# R7FA6T2BD register map
Vendor: Renesas Electronics Corporation; Series: RA6; File version: 1.40.00
CPU: CM33 r0p4, little endian, MPU, FPU, VTOR, 4 interrupt priority bits, 96 interrupts
Registers are 32-bit, read-write, reset 0x0 unless marked. A register's access mark holds for its fields unless they carry their own. Offsets are from the block's base; [hi:lo] are bit positions; {n}, {i} and the like mark numbered series; 'fields as' and 'values as' point back to an identical list.

## MSTP — Module Stop Control
Base 0x40084000
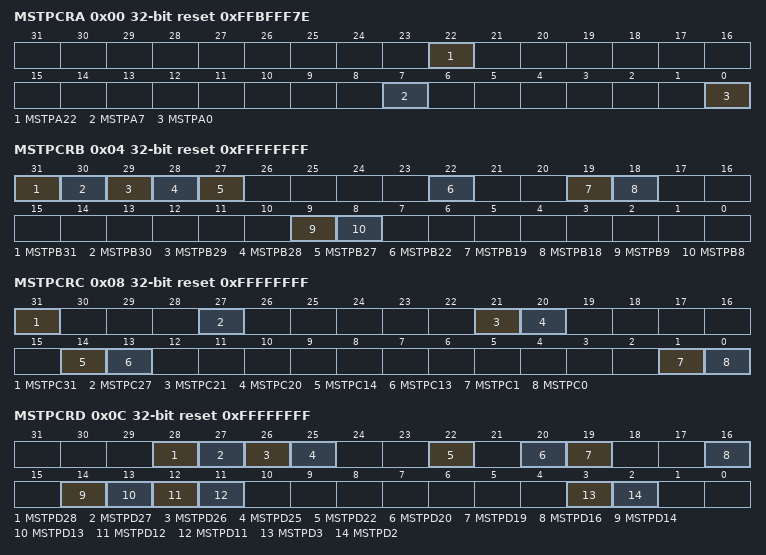
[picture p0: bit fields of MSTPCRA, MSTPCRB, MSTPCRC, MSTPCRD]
0x00 MSTPCRA reset 0xFFBFFF7E — Module Stop Control Register A
  [22] MSTPA22 — DMA Controller/Data Transfer Controller Module Stop
  [7] MSTPA7 — Standby SRAM Module Stop
  [0] MSTPA0 — SRAM0 Module Stop
0x04 MSTPCRB reset 0xFFFFFFFF — Module Stop Control Register B
  [31] MSTPB31 — Serial Communication Interface 0 Module Stop
  [30] MSTPB30 — Serial Communication Interface 1 Module Stop
  [29] MSTPB29 — Serial Communication Interface 2 Module Stop
  [28] MSTPB28 — Serial Communication Interface 3 Module Stop
  [27] MSTPB27 — Serial Communication Interface 4 Module Stop
  [22] MSTPB22 — Serial Communication Interface 9 Module Stop
  [19] MSTPB19 — Serial Peripheral Interface 0 Module Stop
  [18] MSTPB18 — Serial Peripheral Interface 1 Module Stop
  [9] MSTPB9 — I2C Bus Interface 0 Module Stop
  [8] MSTPB8 — I2C Bus Interface 1 Module Stop
0x08 MSTPCRC reset 0xFFFFFFFF — Module Stop Control Register C
  [31] MSTPC31 — Secure Cryptographic Engine Module Stop
  [27] MSTPC27 — CANFD Module Stop
  [21] MSTPC21 — IIR Filter Accelerator Module Stop
  [20] MSTPC20 — Trigonometric Function Unit Module Stop
  [14] MSTPC14 — Event Link Controller Module Stop
  [13] MSTPC13 — Data Operation Circuit Module Stop
  [1] MSTPC1 — Cyclic Redundancy Check Module Stop
  [0] MSTPC0 — Clock Frequency Accuracy Measurement Circuit Module Stop
0x0C MSTPCRD reset 0xFFFFFFFF — Module Stop Control Register D
  [28] MSTPD28 — High,Speed Analog Comparator 0 Module Stop
  [27] MSTPD27 — High,Speed Analog Comparator 1 Module Stop
  [26] MSTPD26 — High,Speed Analog Comparator 2 Module Stop
  [25] MSTPD25 — High,Speed Analog Comparator 3 Module Stop
  [22] MSTPD22 — Temperature Sensor Module Stop
  [20] MSTPD20 — 12-bit D/A Converter 0 Module Stop
  [19] MSTPD19 — 12-bit D/A Converter 1 Module Stop
  [16] MSTPD16 — A/D Converter Module Stop
  [14] MSTPD14 — Port Output Enable for GPT Group A Module Stop
  [13] MSTPD13 — Port Output Enable for GPT Group B Module Stop
  [12] MSTPD12 — Port Output Enable for GPT Group C Module Stop
  [11] MSTPD11 — Port Output Enable for GPT Group D Module Stop
  [3] MSTPD3 — Low Power Asynchronous General Purpose Timer 0 Module Stop
  [2] MSTPD2 — Low Power Asynchronous General Purpose Timer 1 Module Stop
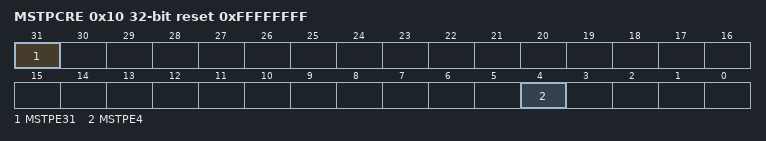
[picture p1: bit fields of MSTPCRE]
0x10 MSTPCRE reset 0xFFFFFFFF — Module Stop Control Register E
  [31] MSTPE31 — General PWM Timer and PWM Delay Generation Circuit Module Stop
  [4] MSTPE4 — Key Interrupt Function Module Stop

## KINT — Key Interrupt Function
Base 0x40085000
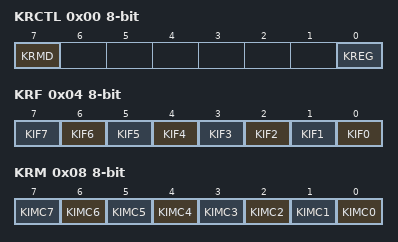
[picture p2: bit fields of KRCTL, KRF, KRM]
0x00 KRCTL 8-bit — Key Return Control Register
  [7] KRMD — Usage of Key Interrupt Flags (KRF.KIF0 to KRF.KIF7)
  [0] KREG — Detection Edge Selection (KR00 to KR07 pins)
0x04 KRF 8-bit — Key Return Flag Register
  [n] KIF{n} (n=0..7) — Key Interrupt Flag n
0x08 KRM 8-bit — Key Return Mode Register
  [n] KIMC{n} (n=0..7) — Key Interrupt Mode Control n

## POEG — Port Output Enable for GPT
Base 0x4008A000
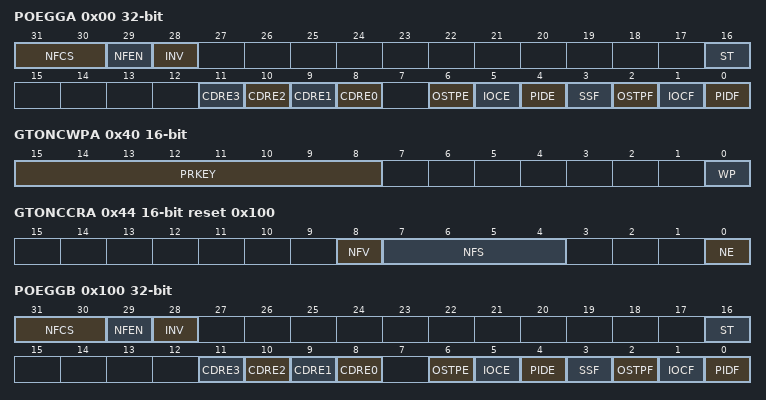
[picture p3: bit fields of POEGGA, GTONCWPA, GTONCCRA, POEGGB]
0x00 POEGGA — POEG Group A Setting Register
  [31:30] NFCS — Noise filter Clock Select
  [29] NFEN — Noise filter Enable
  [28] INV — GTETRGn Input Inverting
  [16] ST ro — GTETRGn Input Status Flag
  [n+8] CDRE{n} (n=0..3) — ACMPHS{n} Enable
  [6] OSTPE — Enable Stopping Output on Stopping of Oscillation
  [5] IOCE — GPT Output Stop Request Enable
  [4] PIDE — Port Input Detection Enable
  [3] SSF — Software Stop Flag
  [2] OSTPF — Oscillation Stop Detection Flag
  [1] IOCF — GPT or ACMPHS Output Stop Request Detection Flag
  [0] PIDF — Port Input Detection Flag
0x40 GTONCWPA 16-bit — GPT Output Stopping Control Group A Write Protection Register
  [15:8] PRKEY — Key Code
  [0] WP — Register Writing Disable
0x44 GTONCCRA 16-bit reset 0x100 — GPT Output Stopping Control Group A Controlling Register
  [8] NFV — Direct Stopping Request Active Sense
  [7:4] NFS — Direct Stopping Request Selection
  [0] NE — Direct Stopping Request Setting
0x100 POEGGB — POEG Group B Setting Register
  fields as POEGGA
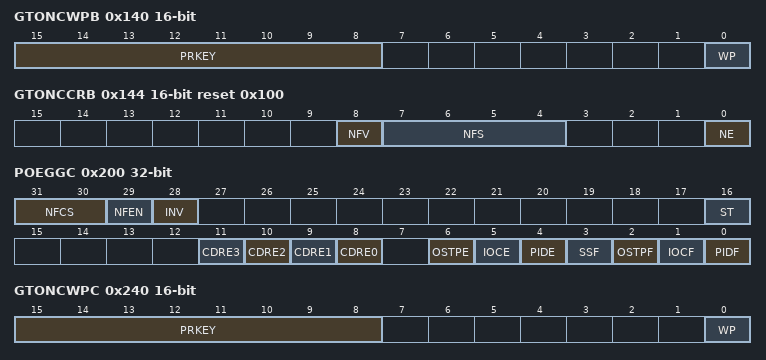
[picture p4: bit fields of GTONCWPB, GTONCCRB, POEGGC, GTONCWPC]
0x140 GTONCWPB 16-bit — GPT Output Stopping Control Group B Write Protection Register
  [15:8] PRKEY — Key Code
  [0] WP — Register Writing Disable
0x144 GTONCCRB 16-bit reset 0x100 — GPT Output Stopping Control Group B Controlling Register
  fields as GTONCCRA
0x200 POEGGC — POEG Group C Setting Register
  fields as POEGGA
0x240 GTONCWPC 16-bit — GPT Output Stopping Control Group C Write Protection Register
  [15:8] PRKEY — Key Code
  [0] WP — Register Writing Disable
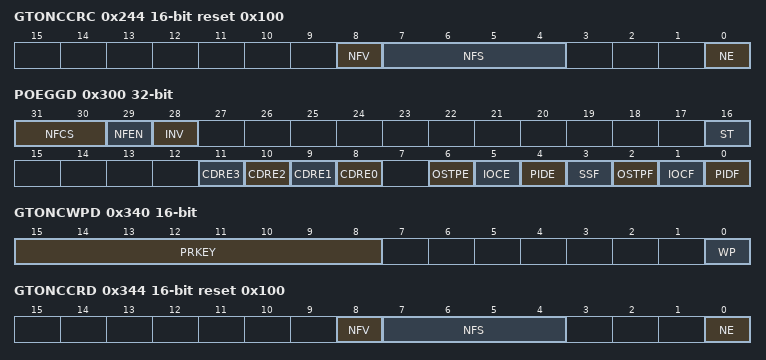
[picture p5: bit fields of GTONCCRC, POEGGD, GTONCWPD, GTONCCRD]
0x244 GTONCCRC 16-bit reset 0x100 — GPT Output Stopping Control Group C Controlling Register
  fields as GTONCCRA
0x300 POEGGD — POEG Group D Setting Register
  fields as POEGGA
0x340 GTONCWPD 16-bit — GPT Output Stopping Control Group D Write Protection Register
  [15:8] PRKEY — Key Code
  [0] WP — Register Writing Disable
0x344 GTONCCRD 16-bit reset 0x100 — GPT Output Stopping Control Group D Controlling Register
  fields as GTONCCRA
